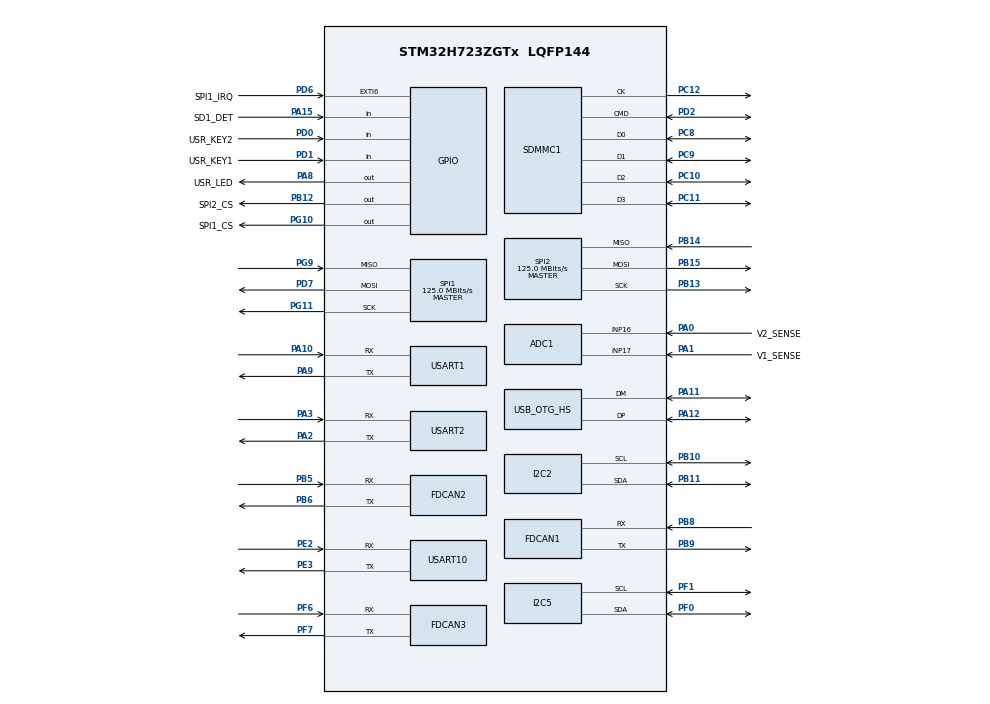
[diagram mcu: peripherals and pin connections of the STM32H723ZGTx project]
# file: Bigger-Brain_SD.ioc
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ADC1.Channel-1\#ChannelRegularConversion=ADC_CHANNEL_17
ADC1.NbrOfConversionFlag=1
ADC1.OffsetNumber-1\#ChannelRegularConversion=ADC_OFFSET_NONE
ADC1.OffsetSignedSaturation-1\#ChannelRegularConversion=DISABLE
ADC1.Rank-1\#ChannelRegularConversion=1
ADC1.SamplingTime-1\#ChannelRegularConversion=ADC_SAMPLETIME_1CYCLE_5
ADC1.master=1
FATFS.BSP.number=1
FATFS._MAX_SS=1024
FATFS0.BSP.STBoard=false
FATFS0.BSP.api=Unknown
FATFS0.BSP.instance=PA15(JTDI)
FATFS0.BSP.ip=GPIO
FATFS0.BSP.mode=Input
FATFS0.BSP.name=Detect_SDIO
FATFS0.BSP.solution=PA15(JTDI)
FDCAN1.CalculateBaudRateNominal=312500
FDCAN1.CalculateTimeBitNominal=3200
FDCAN1.CalculateTimeQuantumNominal=640.0
FDCAN2.CalculateBaudRateNominal=312500
FDCAN2.CalculateTimeBitNominal=3200
FDCAN2.CalculateTimeQuantumNominal=640.0
FDCAN3.CalculateBaudRateNominal=312500
FDCAN3.CalculateTimeBitNominal=3200
FDCAN3.CalculateTimeQuantumNominal=640.0
I2C2.Timing=0x20A0A3F6
I2C5.Timing=0x20A0A3F6
Mcu.Family=STM32H7
Mcu.Name=STM32H723ZGTx
Mcu.Package=LQFP144
NVIC.OTG_HS_IRQn=true\:0\:0\:false\:false\:true\:false\:true\:true
NVIC.PriorityGroup=NVIC_PRIORITYGROUP_4
PA0.GPIO_Label=V2_SENSE
PA0.Mode=IN16-Single-Ended
PA0.Signal=ADC1_INP16
PA1.GPIO_Label=V1_SENSE
PA1.Mode=IN17-Single-Ended
PA1.Signal=ADC1_INP17
PA10.Mode=Asynchronous
PA10.Signal=USART1_RX
PA11.Mode=Device_Only_FS
PA11.Signal=USB_OTG_HS_DM
PA12.Mode=Device_Only_FS
PA12.Signal=USB_OTG_HS_DP
PA13(JTMS/SWDIO).Mode=Serial_Wire
PA13(JTMS/SWDIO).Signal=DEBUG_JTMS-SWDIO
PA14(JTCK/SWCLK).Mode=Serial_Wire
PA14(JTCK/SWCLK).Signal=DEBUG_JTCK-SWCLK
PA15(JTDI).GPIO_Label=SD1_DET
PA15(JTDI).GPIO_PuPd=GPIO_PULLUP
PA15(JTDI).Signal=GPIO_Input
PA2.Mode=Asynchronous
PA2.Signal=USART2_TX
PA3.Mode=Asynchronous
PA3.Signal=USART2_RX
PA8.GPIO_Label=USR_LED
PA8.GPIO_ModeDefaultOutputPP=GPIO_MODE_OUTPUT_OD
PA8.GPIO_PuPd=GPIO_NOPULL
PA8.Signal=GPIO_Output
PA9.Mode=Asynchronous
PA9.Signal=USART1_TX
PB10.Mode=I2C
PB10.Signal=I2C2_SCL
PB11.Mode=I2C
PB11.Signal=I2C2_SDA
PB12.GPIO_Label=SPI2_CS
PB12.Signal=GPIO_Output
PB13.Mode=Full_Duplex_Master
PB13.Signal=SPI2_SCK
PB14.Mode=Full_Duplex_Master
PB14.Signal=SPI2_MISO
PB15.Mode=Full_Duplex_Master
PB15.Signal=SPI2_MOSI
PB5.Mode=FDCAN_Activate
PB5.Signal=FDCAN2_RX
PB6.Mode=FDCAN_Activate
PB6.Signal=FDCAN2_TX
PB8.Mode=FDCAN_Activate
PB8.Signal=FDCAN1_RX
PB9.Mode=FDCAN_Activate
PB9.Signal=FDCAN1_TX
PC10.Mode=SD_4_bits_Wide_bus
PC10.Signal=SDMMC1_D2
PC11.Mode=SD_4_bits_Wide_bus
PC11.Signal=SDMMC1_D3
PC12.Mode=SD_4_bits_Wide_bus
PC12.Signal=SDMMC1_CK
PC14-OSC32_IN.Mode=LSE-External-Oscillator
PC14-OSC32_IN.Signal=RCC_OSC32_IN
PC15-OSC32_OUT.Mode=LSE-External-Oscillator
PC15-OSC32_OUT.Signal=RCC_OSC32_OUT
PC8.Mode=SD_4_bits_Wide_bus
PC8.Signal=SDMMC1_D0
PC9.Mode=SD_4_bits_Wide_bus
PC9.Signal=SDMMC1_D1
PD0.GPIO_Label=USR_KEY2
PD0.GPIO_PuPd=GPIO_NOPULL
PD0.Signal=GPIO_Input
PD1.GPIO_Label=USR_KEY1
PD1.Signal=GPIO_Input
PD2.Mode=SD_4_bits_Wide_bus
PD2.Signal=SDMMC1_CMD
PD6.GPIO_Label=SPI1_IRQ
PD6.Signal=GPXTI6
PD7.Mode=Full_Duplex_Master
PD7.Signal=SPI1_MOSI
PE2.Mode=Asynchronous
PE2.Signal=USART10_RX
PE3.Mode=Asynchronous
PE3.Signal=USART10_TX
PF0.Mode=I2C
PF0.Signal=I2C5_SDA
PF1.Mode=I2C
PF1.Signal=I2C5_SCL
PF6.Mode=FDCAN_Activate
PF6.Signal=FDCAN3_RX
PF7.Mode=FDCAN_Activate
PF7.Signal=FDCAN3_TX
PG10.GPIO_Label=SPI1_CS
PG10.GPIO_PuPd=GPIO_PULLUP
PG10.GPIO_Speed=GPIO_SPEED_FREQ_HIGH
PG10.PinState=GPIO_PIN_SET
PG10.Signal=GPIO_Output
PG11.Mode=Full_Duplex_Master
PG11.Signal=SPI1_SCK
PG9.Mode=Full_Duplex_Master
PG9.Signal=SPI1_MISO
PH0-OSC_IN.Mode=HSE-External-Clock-Source
PH0-OSC_IN.Signal=RCC_OSC_IN
PWR.PVDLevel=PWR_PVDLEVEL_6
ProjectManager.HeapSize=0x200
ProjectManager.StackSize=0x400
ProjectManager.TargetToolchain=STM32CubeIDE
RCC.ADCFreq_Value=96000000
RCC.APB1Freq_Value=125000000
RCC.APB2Freq_Value=125000000
RCC.APB3Freq_Value=125000000
RCC.APB4Freq_Value=125000000
RCC.CortexFreq_Value=500000000
RCC.D1PPRE=RCC_APB3_DIV2
RCC.D2PPRE1=RCC_APB1_DIV2
RCC.D2PPRE2=RCC_APB2_DIV2
RCC.D3PPRE=RCC_APB4_DIV2
RCC.DATA_CACHE_ENABLE=1
RCC.DIVM1=4
RCC.DIVM2=4
RCC.DIVN1=31
RCC.DIVN2=12
RCC.DIVP1=1
RCC.FDCANCLockSelection=RCC_FDCANCLKSOURCE_HSE
RCC.HCLKFreq_Value=250000000
RCC.HPRE=RCC_HCLK_DIV2
RCC.HSE_VALUE=25000000
RCC.INSTRUCTION_CACHE_ENABLE=1
RCC.PLL1_VCI_Range-AdvancedSettings=RCC_PLL1VCIRANGE_1
RCC.PLL1_VCO_SEL-AdvancedSettings=RCC_PLL1VCOMEDIUM
RCC.PLL2FRACN=0
RCC.PLL2_VCI_Range-AdvancedSettings=RCC_PLL2VCIRANGE_1
RCC.PLL2_VCO_SEL-AdvancedSettings=RCC_PLL2VCOWIDE
RCC.PLL3FRACN=0
RCC.PLL3_VCO_SEL-AdvancedSettings=RCC_PLL3VCOMEDIUM
RCC.PLLFRACN=2048
RCC.PREFETCH_ENABLE=1
RCC.PWREXT_OverDrive=PWREXT_OverDrive_DESACTIVATED
RCC.PWR_Regulator_Voltage_Scale=PWR_REGULATOR_VOLTAGE_SCALE0
RCC.ProductRev=revV
RCC.RCC_TIM_PRescaler_Selection=RCC_TIMPRES_ACTIVATED
RCC.SDMMC1CLockSelection=RCC_SDMMCCLKSOURCE_PLL2
RCC.SYSCLKFreq_VALUE=500000000
RCC.SYSCLKSource=RCC_SYSCLKSOURCE_PLLCLK
RCC.SupplySource=PWR_LDO_SUPPLY
RCC.USBCLockSelection=RCC_USBCLKSOURCE_HSI48
RCC.USBFreq_Value=48000000
SDMMC1.ClockDiv=4
SPI1.CalculateBaudRate=125.0 MBits/s
SPI1.Direction=SPI_DIRECTION_2LINES
SPI1.Mode=SPI_MODE_MASTER
SPI1.VirtualType=VM_MASTER
SPI2.CalculateBaudRate=125.0 MBits/s
SPI2.Direction=SPI_DIRECTION_2LINES
SPI2.Mode=SPI_MODE_MASTER
SPI2.VirtualType=VM_MASTER
USART1.VirtualMode-Asynchronous=VM_ASYNC
USART10.VirtualMode-Asynchronous=VM_ASYNC
USART2.VirtualMode-Asynchronous=VM_ASYNC
USB_DEVICE.CLASS_NAME_HS=CDC
USB_DEVICE.MANUFACTURER_STRING=Bigger-Brain
USB_DEVICE.PRODUCT_STRING_CDC_HS=Scott CJX
USB_DEVICE.VirtualMode=Cdc
USB_DEVICE.VirtualModeHS=Cdc_HS
USB_OTG_HS.VirtualMode-Device_Only_FS=Device_Only_FS
VP_FATFS_VS_SDIO.Mode=SDIO
VP_PWR_V_PVD_IN.Mode=Mode_PVD_Int
VP_USB_DEVICE_VS_USB_DEVICE_CDC_HS.Mode=CDC_HS
board=custom

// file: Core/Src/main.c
/* USER CODE BEGIN Header */
/**
 ******************************************************************************
 * @file           : main.c
 * @brief          : Main program body
 ******************************************************************************
 * @attention
 *
 * Copyright (c) 2024 STMicroelectronics.
 * All rights reserved.
 *
 * This software is licensed under terms that can be found in the LICENSE file
 * in the root directory of this software component.
 * If no LICENSE file comes with this software, it is provided AS-IS.
 *
 ******************************************************************************
 */
/* USER CODE END Header */
#include "main.h"
#include "fatfs.h"
#include "usb_device.h"

/* USER CODE BEGIN Includes */

// #include "usbd_cdc_if.h"
// #include "ffconf.h"

// #include <stdio.h>
// #include <stdlib.h>
// #include <string.h>

// moved to app_sdcard

/* USER CODE END Includes */

ADC_HandleTypeDef hadc1;

FDCAN_HandleTypeDef hfdcan1;
FDCAN_HandleTypeDef hfdcan2;
FDCAN_HandleTypeDef hfdcan3;

I2C_HandleTypeDef hi2c2;
I2C_HandleTypeDef hi2c5;

SD_HandleTypeDef hsd1;

SPI_HandleTypeDef hspi1;
SPI_HandleTypeDef hspi2;

UART_HandleTypeDef huart1;
UART_HandleTypeDef huart2;
UART_HandleTypeDef huart10;

void SystemClock_Config(void);
void PeriphCommonClock_Config(void);
static void MX_GPIO_Init(void);
static void MX_FDCAN1_Init(void);
static void MX_FDCAN2_Init(void);
static void MX_FDCAN3_Init(void);
static void MX_SDMMC1_SD_Init(void);
static void MX_I2C2_Init(void);
static void MX_SPI2_Init(void);
static void MX_USART1_UART_Init(void);
static void MX_USART2_UART_Init(void);
static void MX_ADC1_Init(void);
static void MX_I2C5_Init(void);
static void MX_SPI1_Init(void);
static void MX_USART10_UART_Init(void);

/* USER CODE BEGIN 0 */

// /* Function to read directory contents and transmit via CDC */
// int read_directory(char *path)
// {
//   DIR dir;
//   FILINFO fno;
//   FRESULT res;

//   if (f_opendir(&dir, path) != FR_OK)
//   {
//     CDC_Transmit_HS((uint8_t *)"Failed to open directory\n", strlen("Failed to open directory\n"));
//     return 1;
//   }

//   while ((res = f_readdir(&dir, &fno)) == FR_OK && fno.fname[0] != 0)
//   {
//     if (fno.fattrib & AM_DIR)
//     {
//       // Directory
//       CDC_Transmit_HS((uint8_t *)"\t<DIR> ", strlen("\t<DIR> "));
//     }
//     else
//     {
//       // File
//       CDC_Transmit_HS((uint8_t *)"\t", strlen("\t"));
//     }
//     CDC_Transmit_HS((uint8_t *)fno.fname, strlen(fno.fname));
//     CDC_Transmit_HS((uint8_t *)"\n", strlen("\n"));
//   }

//   f_closedir(&dir); // Close the directory

//   return 0;
// }

// /* Function to read a file on the SD card and transmit via CDC */
// int read_file(char *filename) {
//   FIL file;
//   FRESULT res;
//   UINT bytes_read;
//   char buffer[512]; // Adjust buffer size as needed

//   if (f_open(&file, filename, FA_READ) != FR_OK) {
//     CDC_Transmit_HS((uint8_t *)"Failed to open file: ", strlen("Failed to open file: "));
//     CDC_Transmit_HS((uint8_t *)filename, strlen(filename));
//     CDC_Transmit_HS((uint8_t *)"\n", strlen("\n"));
//     return 1;
//   }

//   // Read the file content into the buffer
//   while ((res = f_read(&file, buffer, sizeof(buffer), &bytes_read)) == FR_OK && bytes_read > 0) {
//     // Transmit the read data via CDC
//     CDC_Transmit_HS((uint8_t *)buffer, bytes_read);
//   }

//   if (res != FR_OK) {
//     CDC_Transmit_HS((uint8_t *)"Error reading file: ", strlen("Error reading file: "));
//     CDC_Transmit_HS((uint8_t *)filename, strlen(filename));
//     CDC_Transmit_HS((uint8_t *)"\n", strlen("\n"));
//     f_close(&file);
//     return 1;
//   }

//   CDC_Transmit_HS((uint8_t *)"Finished reading file: ", strlen("Finished reading file: "));
//   CDC_Transmit_HS((uint8_t *)filename, strlen(filename));
//   CDC_Transmit_HS((uint8_t *)"\n", strlen("\n"));
//   f_close(&file);

//   return 0;
// }

// moved to app_sdcard

/* USER CODE END 0 */

int main(void)
{

  /* MCU Configuration--------------------------------------------------------*/

  /* Reset of all peripherals, Initializes the Flash interface and the Systick. */
  HAL_Init();

  /* Configure the system clock */
  SystemClock_Config();

/* Configure the peripherals common clocks */
  PeriphCommonClock_Config();

  /* Initialize all configured peripherals */
  MX_GPIO_Init();
  MX_FDCAN1_Init();
  MX_FDCAN2_Init();
  MX_FDCAN3_Init();
  MX_SDMMC1_SD_Init();
  MX_I2C2_Init();
  MX_SPI2_Init();
  MX_USART1_UART_Init();
  MX_USART2_UART_Init();
  MX_ADC1_Init();
  MX_I2C5_Init();
  MX_SPI1_Init();
  MX_USART10_UART_Init();
  MX_USB_DEVICE_Init();
  MX_FATFS_Init();

  /* Infinite loop */
  while (1)
  {

    /* USER CODE BEGIN 3 */
//
    if (HAL_GPIO_ReadPin(USR_KEY1_GPIO_Port, USR_KEY1_Pin))
    {

      // todo

      while (HAL_GPIO_ReadPin(USR_KEY1_GPIO_Port, USR_KEY1_Pin))
      {
        ;
      }
    }

    HAL_GPIO_WritePin(USR_LED_GPIO_Port, USR_LED_Pin, HAL_GPIO_ReadPin(SD1_DET_GPIO_Port, SD1_DET_Pin));
    HAL_Delay(500);
  }
  /* USER CODE END 3 */
}

void SystemClock_Config(void)
{
  RCC_OscInitTypeDef RCC_OscInitStruct = {0};
  RCC_ClkInitTypeDef RCC_ClkInitStruct = {0};

  /** Supply configuration update enable
  */
  HAL_PWREx_ConfigSupply(PWR_LDO_SUPPLY);

  /** Configure the main internal regulator output voltage
  */
  __HAL_PWR_VOLTAGESCALING_CONFIG(PWR_REGULATOR_VOLTAGE_SCALE0);

  while(!__HAL_PWR_GET_FLAG(PWR_FLAG_VOSRDY)) {}

  /** Initializes the RCC Oscillators according to the specified parameters
  * in the RCC_OscInitTypeDef structure.
  */
  RCC_OscInitStruct.OscillatorType = RCC_OSCILLATORTYPE_HSI48|RCC_OSCILLATORTYPE_HSI
                              |RCC_OSCILLATORTYPE_HSE;
  RCC_OscInitStruct.HSEState = RCC_HSE_BYPASS;
  RCC_OscInitStruct.HSIState = RCC_HSI_DIV1;
  RCC_OscInitStruct.HSICalibrationValue = 64;
  RCC_OscInitStruct.HSI48State = RCC_HSI48_ON;
  RCC_OscInitStruct.PLL.PLLState = RCC_PLL_ON;
  RCC_OscInitStruct.PLL.PLLSource = RCC_PLLSOURCE_HSI;
  RCC_OscInitStruct.PLL.PLLM = 4;
  RCC_OscInitStruct.PLL.PLLN = 31;
  RCC_OscInitStruct.PLL.PLLP = 1;
  RCC_OscInitStruct.PLL.PLLQ = 2;
  RCC_OscInitStruct.PLL.PLLR = 2;
  RCC_OscInitStruct.PLL.PLLRGE = RCC_PLL1VCIRANGE_3;
  RCC_OscInitStruct.PLL.PLLVCOSEL = RCC_PLL1VCOWIDE;
  RCC_OscInitStruct.PLL.PLLFRACN = 2048;
  if (HAL_RCC_OscConfig(&RCC_OscInitStruct) != HAL_OK)
  {
    Error_Handler();
  }

  /** Initializes the CPU, AHB and APB buses clocks
  */
  RCC_ClkInitStruct.ClockType = RCC_CLOCKTYPE_HCLK|RCC_CLOCKTYPE_SYSCLK
                              |RCC_CLOCKTYPE_PCLK1|RCC_CLOCKTYPE_PCLK2
                              |RCC_CLOCKTYPE_D3PCLK1|RCC_CLOCKTYPE_D1PCLK1;
  RCC_ClkInitStruct.SYSCLKSource = RCC_SYSCLKSOURCE_PLLCLK;
  RCC_ClkInitStruct.SYSCLKDivider = RCC_SYSCLK_DIV1;
  RCC_ClkInitStruct.AHBCLKDivider = RCC_HCLK_DIV2;
  RCC_ClkInitStruct.APB3CLKDivider = RCC_APB3_DIV2;
  RCC_ClkInitStruct.APB1CLKDivider = RCC_APB1_DIV2;
  RCC_ClkInitStruct.APB2CLKDivider = RCC_APB2_DIV2;
  RCC_ClkInitStruct.APB4CLKDivider = RCC_APB4_DIV2;

  if (HAL_RCC_ClockConfig(&RCC_ClkInitStruct, FLASH_LATENCY_3) != HAL_OK)
  {
    Error_Handler();
  }
}

void PeriphCommonClock_Config(void)
{
  RCC_PeriphCLKInitTypeDef PeriphClkInitStruct = {0};

  /** Initializes the peripherals clock
  */
  PeriphClkInitStruct.PeriphClockSelection = RCC_PERIPHCLK_ADC|RCC_PERIPHCLK_SDMMC
                              |RCC_PERIPHCLK_TIM;
  PeriphClkInitStruct.PLL2.PLL2M = 4;
  PeriphClkInitStruct.PLL2.PLL2N = 12;
  PeriphClkInitStruct.PLL2.PLL2P = 2;
  PeriphClkInitStruct.PLL2.PLL2Q = 2;
  PeriphClkInitStruct.PLL2.PLL2R = 2;
  PeriphClkInitStruct.PLL2.PLL2RGE = RCC_PLL2VCIRANGE_3;
  PeriphClkInitStruct.PLL2.PLL2VCOSEL = RCC_PLL2VCOWIDE;
  PeriphClkInitStruct.PLL2.PLL2FRACN = 0;
  PeriphClkInitStruct.SdmmcClockSelection = RCC_SDMMCCLKSOURCE_PLL2;
  PeriphClkInitStruct.AdcClockSelection = RCC_ADCCLKSOURCE_PLL2;
  PeriphClkInitStruct.TIMPresSelection = RCC_TIMPRES_ACTIVATED;

  if (HAL_RCCEx_PeriphCLKConfig(&PeriphClkInitStruct) != HAL_OK)
  {
    Error_Handler();
  }
}

static void MX_ADC1_Init(void)
{

  ADC_MultiModeTypeDef multimode = {0};
  ADC_ChannelConfTypeDef sConfig = {0};

  /** Common config
  */
  hadc1.Instance = ADC1;
  hadc1.Init.ClockPrescaler = ADC_CLOCK_ASYNC_DIV1;
  hadc1.Init.Resolution = ADC_RESOLUTION_16B;
  hadc1.Init.ScanConvMode = ADC_SCAN_DISABLE;
  hadc1.Init.EOCSelection = ADC_EOC_SINGLE_CONV;
  hadc1.Init.LowPowerAutoWait = DISABLE;
  hadc1.Init.ContinuousConvMode = DISABLE;
  hadc1.Init.NbrOfConversion = 1;
  hadc1.Init.DiscontinuousConvMode = DISABLE;
  hadc1.Init.ExternalTrigConv = ADC_SOFTWARE_START;
  hadc1.Init.ExternalTrigConvEdge = ADC_EXTERNALTRIGCONVEDGE_NONE;
  hadc1.Init.ConversionDataManagement = ADC_CONVERSIONDATA_DR;
  hadc1.Init.Overrun = ADC_OVR_DATA_PRESERVED;
  hadc1.Init.LeftBitShift = ADC_LEFTBITSHIFT_NONE;
  hadc1.Init.OversamplingMode = DISABLE;
  if (HAL_ADC_Init(&hadc1) != HAL_OK)
  {
    Error_Handler();
  }

  /** Configure the ADC multi-mode
  */
  multimode.Mode = ADC_MODE_INDEPENDENT;
  if (HAL_ADCEx_MultiModeConfigChannel(&hadc1, &multimode) != HAL_OK)
  {
    Error_Handler();
  }

  /** Configure Regular Channel
  */
  sConfig.Channel = ADC_CHANNEL_17;
  sConfig.Rank = ADC_REGULAR_RANK_1;
  sConfig.SamplingTime = ADC_SAMPLETIME_1CYCLE_5;
  sConfig.SingleDiff = ADC_SINGLE_ENDED;
  sConfig.OffsetNumber = ADC_OFFSET_NONE;
  sConfig.Offset = 0;
  sConfig.OffsetSignedSaturation = DISABLE;
  if (HAL_ADC_ConfigChannel(&hadc1, &sConfig) != HAL_OK)
  {
    Error_Handler();
  }

}

static void MX_FDCAN1_Init(void)
{

  hfdcan1.Instance = FDCAN1;
  hfdcan1.Init.FrameFormat = FDCAN_FRAME_CLASSIC;
  hfdcan1.Init.Mode = FDCAN_MODE_NORMAL;
  hfdcan1.Init.AutoRetransmission = DISABLE;
  hfdcan1.Init.TransmitPause = DISABLE;
  hfdcan1.Init.ProtocolException = DISABLE;
  hfdcan1.Init.NominalPrescaler = 16;
  hfdcan1.Init.NominalSyncJumpWidth = 1;
  hfdcan1.Init.NominalTimeSeg1 = 2;
  hfdcan1.Init.NominalTimeSeg2 = 2;
  hfdcan1.Init.DataPrescaler = 1;
  hfdcan1.Init.DataSyncJumpWidth = 1;
  hfdcan1.Init.DataTimeSeg1 = 1;
  hfdcan1.Init.DataTimeSeg2 = 1;
  hfdcan1.Init.MessageRAMOffset = 0;
  hfdcan1.Init.StdFiltersNbr = 0;
  hfdcan1.Init.ExtFiltersNbr = 0;
  hfdcan1.Init.RxFifo0ElmtsNbr = 0;
  hfdcan1.Init.RxFifo0ElmtSize = FDCAN_DATA_BYTES_8;
  hfdcan1.Init.RxFifo1ElmtsNbr = 0;
  hfdcan1.Init.RxFifo1ElmtSize = FDCAN_DATA_BYTES_8;
  hfdcan1.Init.RxBuffersNbr = 0;
  hfdcan1.Init.RxBufferSize = FDCAN_DATA_BYTES_8;
  hfdcan1.Init.TxEventsNbr = 0;
  hfdcan1.Init.TxBuffersNbr = 0;
  hfdcan1.Init.TxFifoQueueElmtsNbr = 0;
  hfdcan1.Init.TxFifoQueueMode = FDCAN_TX_FIFO_OPERATION;
  hfdcan1.Init.TxElmtSize = FDCAN_DATA_BYTES_8;
  if (HAL_FDCAN_Init(&hfdcan1) != HAL_OK)
  {
    Error_Handler();
  }

}

static void MX_FDCAN2_Init(void)
{

  hfdcan2.Instance = FDCAN2;
  hfdcan2.Init.FrameFormat = FDCAN_FRAME_CLASSIC;
  hfdcan2.Init.Mode = FDCAN_MODE_NORMAL;
  hfdcan2.Init.AutoRetransmission = DISABLE;
  hfdcan2.Init.TransmitPause = DISABLE;
  hfdcan2.Init.ProtocolException = DISABLE;
  hfdcan2.Init.NominalPrescaler = 16;
  hfdcan2.Init.NominalSyncJumpWidth = 1;
  hfdcan2.Init.NominalTimeSeg1 = 2;
  hfdcan2.Init.NominalTimeSeg2 = 2;
  hfdcan2.Init.DataPrescaler = 1;
  hfdcan2.Init.DataSyncJumpWidth = 1;
  hfdcan2.Init.DataTimeSeg1 = 1;
  hfdcan2.Init.DataTimeSeg2 = 1;
  hfdcan2.Init.MessageRAMOffset = 0;
  hfdcan2.Init.StdFiltersNbr = 0;
  hfdcan2.Init.ExtFiltersNbr = 0;
  hfdcan2.Init.RxFifo0ElmtsNbr = 0;
  hfdcan2.Init.RxFifo0ElmtSize = FDCAN_DATA_BYTES_8;
  hfdcan2.Init.RxFifo1ElmtsNbr = 0;
  hfdcan2.Init.RxFifo1ElmtSize = FDCAN_DATA_BYTES_8;
  hfdcan2.Init.RxBuffersNbr = 0;
  hfdcan2.Init.RxBufferSize = FDCAN_DATA_BYTES_8;
  hfdcan2.Init.TxEventsNbr = 0;
  hfdcan2.Init.TxBuffersNbr = 0;
  hfdcan2.Init.TxFifoQueueElmtsNbr = 0;
  hfdcan2.Init.TxFifoQueueMode = FDCAN_TX_FIFO_OPERATION;
  hfdcan2.Init.TxElmtSize = FDCAN_DATA_BYTES_8;
  if (HAL_FDCAN_Init(&hfdcan2) != HAL_OK)
  {
    Error_Handler();
  }

}

static void MX_FDCAN3_Init(void)
{

  hfdcan3.Instance = FDCAN3;
  hfdcan3.Init.FrameFormat = FDCAN_FRAME_CLASSIC;
  hfdcan3.Init.Mode = FDCAN_MODE_NORMAL;
  hfdcan3.Init.AutoRetransmission = DISABLE;
  hfdcan3.Init.TransmitPause = DISABLE;
  hfdcan3.Init.ProtocolException = DISABLE;
  hfdcan3.Init.NominalPrescaler = 16;
  hfdcan3.Init.NominalSyncJumpWidth = 1;
  hfdcan3.Init.NominalTimeSeg1 = 2;
  hfdcan3.Init.NominalTimeSeg2 = 2;
  hfdcan3.Init.DataPrescaler = 1;
  hfdcan3.Init.DataSyncJumpWidth = 1;
  hfdcan3.Init.DataTimeSeg1 = 1;
  hfdcan3.Init.DataTimeSeg2 = 1;
  hfdcan3.Init.MessageRAMOffset = 0;
  hfdcan3.Init.StdFiltersNbr = 0;
  hfdcan3.Init.ExtFiltersNbr = 0;
  hfdcan3.Init.RxFifo0ElmtsNbr = 0;
  hfdcan3.Init.RxFifo0ElmtSize = FDCAN_DATA_BYTES_8;
  hfdcan3.Init.RxFifo1ElmtsNbr = 0;
  hfdcan3.Init.RxFifo1ElmtSize = FDCAN_DATA_BYTES_8;
  hfdcan3.Init.RxBuffersNbr = 0;
  hfdcan3.Init.RxBufferSize = FDCAN_DATA_BYTES_8;
  hfdcan3.Init.TxEventsNbr = 0;
  hfdcan3.Init.TxBuffersNbr = 0;
  hfdcan3.Init.TxFifoQueueElmtsNbr = 0;
  hfdcan3.Init.TxFifoQueueMode = FDCAN_TX_FIFO_OPERATION;
  hfdcan3.Init.TxElmtSize = FDCAN_DATA_BYTES_8;
  if (HAL_FDCAN_Init(&hfdcan3) != HAL_OK)
  {
    Error_Handler();
  }

}

static void MX_I2C2_Init(void)
{

  hi2c2.Instance = I2C2;
  hi2c2.Init.Timing = 0x20A0A3F6;
  hi2c2.Init.OwnAddress1 = 0;
  hi2c2.Init.AddressingMode = I2C_ADDRESSINGMODE_7BIT;
  hi2c2.Init.DualAddressMode = I2C_DUALADDRESS_DISABLE;
  hi2c2.Init.OwnAddress2 = 0;
  hi2c2.Init.OwnAddress2Masks = I2C_OA2_NOMASK;
  hi2c2.Init.GeneralCallMode = I2C_GENERALCALL_DISABLE;
  hi2c2.Init.NoStretchMode = I2C_NOSTRETCH_DISABLE;
  if (HAL_I2C_Init(&hi2c2) != HAL_OK)
  {
    Error_Handler();
  }

  /** Configure Analogue filter
  */
  if (HAL_I2CEx_ConfigAnalogFilter(&hi2c2, I2C_ANALOGFILTER_ENABLE) != HAL_OK)
  {
    Error_Handler();
  }

  /** Configure Digital filter
  */
  if (HAL_I2CEx_ConfigDigitalFilter(&hi2c2, 0) != HAL_OK)
  {
    Error_Handler();
  }

}

static void MX_I2C5_Init(void)
{

  hi2c5.Instance = I2C5;
  hi2c5.Init.Timing = 0x20A0A3F6;
  hi2c5.Init.OwnAddress1 = 0;
  hi2c5.Init.AddressingMode = I2C_ADDRESSINGMODE_7BIT;
  hi2c5.Init.DualAddressMode = I2C_DUALADDRESS_DISABLE;
  hi2c5.Init.OwnAddress2 = 0;
  hi2c5.Init.OwnAddress2Masks = I2C_OA2_NOMASK;
  hi2c5.Init.GeneralCallMode = I2C_GENERALCALL_DISABLE;
  hi2c5.Init.NoStretchMode = I2C_NOSTRETCH_DISABLE;
  if (HAL_I2C_Init(&hi2c5) != HAL_OK)
  {
    Error_Handler();
  }

  /** Configure Analogue filter
  */
  if (HAL_I2CEx_ConfigAnalogFilter(&hi2c5, I2C_ANALOGFILTER_ENABLE) != HAL_OK)
  {
    Error_Handler();
  }

  /** Configure Digital filter
  */
  if (HAL_I2CEx_ConfigDigitalFilter(&hi2c5, 0) != HAL_OK)
  {
    Error_Handler();
  }

}

static void MX_SDMMC1_SD_Init(void)
{

  hsd1.Instance = SDMMC1;
  hsd1.Init.ClockEdge = SDMMC_CLOCK_EDGE_RISING;
  hsd1.Init.ClockPowerSave = SDMMC_CLOCK_POWER_SAVE_DISABLE;
  hsd1.Init.BusWide = SDMMC_BUS_WIDE_4B;
  hsd1.Init.HardwareFlowControl = SDMMC_HARDWARE_FLOW_CONTROL_DISABLE;
  hsd1.Init.ClockDiv = 4;

}

static void MX_SPI1_Init(void)
{

  /* SPI1 parameter configuration*/
  hspi1.Instance = SPI1;
  hspi1.Init.Mode = SPI_MODE_MASTER;
  hspi1.Init.Direction = SPI_DIRECTION_2LINES;
  hspi1.Init.DataSize = SPI_DATASIZE_4BIT;
  hspi1.Init.CLKPolarity = SPI_POLARITY_LOW;
  hspi1.Init.CLKPhase = SPI_PHASE_1EDGE;
  hspi1.Init.NSS = SPI_NSS_SOFT;
  hspi1.Init.BaudRatePrescaler = SPI_BAUDRATEPRESCALER_2;
  hspi1.Init.FirstBit = SPI_FIRSTBIT_MSB;
  hspi1.Init.TIMode = SPI_TIMODE_DISABLE;
  hspi1.Init.CRCCalculation = SPI_CRCCALCULATION_DISABLE;
  hspi1.Init.CRCPolynomial = 0x0;
  hspi1.Init.NSSPMode = SPI_NSS_PULSE_ENABLE;
  hspi1.Init.NSSPolarity = SPI_NSS_POLARITY_LOW;
  hspi1.Init.FifoThreshold = SPI_FIFO_THRESHOLD_01DATA;
  hspi1.Init.TxCRCInitializationPattern = SPI_CRC_INITIALIZATION_ALL_ZERO_PATTERN;
  hspi1.Init.RxCRCInitializationPattern = SPI_CRC_INITIALIZATION_ALL_ZERO_PATTERN;
  hspi1.Init.MasterSSIdleness = SPI_MASTER_SS_IDLENESS_00CYCLE;
  hspi1.Init.MasterInterDataIdleness = SPI_MASTER_INTERDATA_IDLENESS_00CYCLE;
  hspi1.Init.MasterReceiverAutoSusp = SPI_MASTER_RX_AUTOSUSP_DISABLE;
  hspi1.Init.MasterKeepIOState = SPI_MASTER_KEEP_IO_STATE_DISABLE;
  hspi1.Init.IOSwap = SPI_IO_SWAP_DISABLE;
  if (HAL_SPI_Init(&hspi1) != HAL_OK)
  {
    Error_Handler();
  }

}

static void MX_SPI2_Init(void)
{

  /* SPI2 parameter configuration*/
  hspi2.Instance = SPI2;
  hspi2.Init.Mode = SPI_MODE_MASTER;
  hspi2.Init.Direction = SPI_DIRECTION_2LINES;
  hspi2.Init.DataSize = SPI_DATASIZE_4BIT;
  hspi2.Init.CLKPolarity = SPI_POLARITY_LOW;
  hspi2.Init.CLKPhase = SPI_PHASE_1EDGE;
  hspi2.Init.NSS = SPI_NSS_SOFT;
  hspi2.Init.BaudRatePrescaler = SPI_BAUDRATEPRESCALER_2;
  hspi2.Init.FirstBit = SPI_FIRSTBIT_MSB;
  hspi2.Init.TIMode = SPI_TIMODE_DISABLE;
  hspi2.Init.CRCCalculation = SPI_CRCCALCULATION_DISABLE;
  hspi2.Init.CRCPolynomial = 0x0;
  hspi2.Init.NSSPMode = SPI_NSS_PULSE_ENABLE;
  hspi2.Init.NSSPolarity = SPI_NSS_POLARITY_LOW;
  hspi2.Init.FifoThreshold = SPI_FIFO_THRESHOLD_01DATA;
  hspi2.Init.TxCRCInitializationPattern = SPI_CRC_INITIALIZATION_ALL_ZERO_PATTERN;
  hspi2.Init.RxCRCInitializationPattern = SPI_CRC_INITIALIZATION_ALL_ZERO_PATTERN;
  hspi2.Init.MasterSSIdleness = SPI_MASTER_SS_IDLENESS_00CYCLE;
  hspi2.Init.MasterInterDataIdleness = SPI_MASTER_INTERDATA_IDLENESS_00CYCLE;
  hspi2.Init.MasterReceiverAutoSusp = SPI_MASTER_RX_AUTOSUSP_DISABLE;
  hspi2.Init.MasterKeepIOState = SPI_MASTER_KEEP_IO_STATE_DISABLE;
  hspi2.Init.IOSwap = SPI_IO_SWAP_DISABLE;
  if (HAL_SPI_Init(&hspi2) != HAL_OK)
  {
    Error_Handler();
  }

}

static void MX_USART1_UART_Init(void)
{

  huart1.Instance = USART1;
  huart1.Init.BaudRate = 115200;
  huart1.Init.WordLength = UART_WORDLENGTH_8B;
  huart1.Init.StopBits = UART_STOPBITS_1;
  huart1.Init.Parity = UART_PARITY_NONE;
  huart1.Init.Mode = UART_MODE_TX_RX;
  huart1.Init.HwFlowCtl = UART_HWCONTROL_NONE;
  huart1.Init.OverSampling = UART_OVERSAMPLING_16;
  huart1.Init.OneBitSampling = UART_ONE_BIT_SAMPLE_DISABLE;
  huart1.Init.ClockPrescaler = UART_PRESCALER_DIV1;
  huart1.AdvancedInit.AdvFeatureInit = UART_ADVFEATURE_NO_INIT;
  if (HAL_UART_Init(&huart1) != HAL_OK)
  {
    Error_Handler();
  }
  if (HAL_UARTEx_SetTxFifoThreshold(&huart1, UART_TXFIFO_THRESHOLD_1_8) != HAL_OK)
  {
    Error_Handler();
  }
  if (HAL_UARTEx_SetRxFifoThreshold(&huart1, UART_RXFIFO_THRESHOLD_1_8) != HAL_OK)
  {
    Error_Handler();
  }
  if (HAL_UARTEx_DisableFifoMode(&huart1) != HAL_OK)
  {
    Error_Handler();
  }

}

static void MX_USART2_UART_Init(void)
{

  huart2.Instance = USART2;
  huart2.Init.BaudRate = 115200;
  huart2.Init.WordLength = UART_WORDLENGTH_8B;
  huart2.Init.StopBits = UART_STOPBITS_1;
  huart2.Init.Parity = UART_PARITY_NONE;
  huart2.Init.Mode = UART_MODE_TX_RX;
  huart2.Init.HwFlowCtl = UART_HWCONTROL_NONE;
  huart2.Init.OverSampling = UART_OVERSAMPLING_16;
  huart2.Init.OneBitSampling = UART_ONE_BIT_SAMPLE_DISABLE;
  huart2.Init.ClockPrescaler = UART_PRESCALER_DIV1;
  huart2.AdvancedInit.AdvFeatureInit = UART_ADVFEATURE_NO_INIT;
  if (HAL_UART_Init(&huart2) != HAL_OK)
  {
    Error_Handler();
  }
  if (HAL_UARTEx_SetTxFifoThreshold(&huart2, UART_TXFIFO_THRESHOLD_1_8) != HAL_OK)
  {
    Error_Handler();
  }
  if (HAL_UARTEx_SetRxFifoThreshold(&huart2, UART_RXFIFO_THRESHOLD_1_8) != HAL_OK)
  {
    Error_Handler();
  }
  if (HAL_UARTEx_DisableFifoMode(&huart2) != HAL_OK)
  {
    Error_Handler();
  }

}

static void MX_USART10_UART_Init(void)
{

  huart10.Instance = USART10;
  huart10.Init.BaudRate = 115200;
  huart10.Init.WordLength = UART_WORDLENGTH_8B;
  huart10.Init.StopBits = UART_STOPBITS_1;
  huart10.Init.Parity = UART_PARITY_NONE;
  huart10.Init.Mode = UART_MODE_TX_RX;
  huart10.Init.HwFlowCtl = UART_HWCONTROL_NONE;
  huart10.Init.OverSampling = UART_OVERSAMPLING_16;
  huart10.Init.OneBitSampling = UART_ONE_BIT_SAMPLE_DISABLE;
  huart10.Init.ClockPrescaler = UART_PRESCALER_DIV1;
  huart10.AdvancedInit.AdvFeatureInit = UART_ADVFEATURE_NO_INIT;
  if (HAL_UART_Init(&huart10) != HAL_OK)
  {
    Error_Handler();
  }
  if (HAL_UARTEx_SetTxFifoThreshold(&huart10, UART_TXFIFO_THRESHOLD_1_8) != HAL_OK)
  {
    Error_Handler();
  }
  if (HAL_UARTEx_SetRxFifoThreshold(&huart10, UART_RXFIFO_THRESHOLD_1_8) != HAL_OK)
  {
    Error_Handler();
  }
  if (HAL_UARTEx_DisableFifoMode(&huart10) != HAL_OK)
  {
    Error_Handler();
  }

}

static void MX_GPIO_Init(void)
{
  GPIO_InitTypeDef GPIO_InitStruct = {0};

  /* GPIO Ports Clock Enable */
  __HAL_RCC_GPIOE_CLK_ENABLE();
  __HAL_RCC_GPIOC_CLK_ENABLE();
  __HAL_RCC_GPIOF_CLK_ENABLE();
  __HAL_RCC_GPIOH_CLK_ENABLE();
  __HAL_RCC_GPIOA_CLK_ENABLE();
  __HAL_RCC_GPIOB_CLK_ENABLE();
  __HAL_RCC_GPIOD_CLK_ENABLE();
  __HAL_RCC_GPIOG_CLK_ENABLE();

  /*Configure GPIO pin Output Level */
  HAL_GPIO_WritePin(SPI2_CS_GPIO_Port, SPI2_CS_Pin, GPIO_PIN_RESET);

  /*Configure GPIO pin Output Level */
  HAL_GPIO_WritePin(USR_LED_GPIO_Port, USR_LED_Pin, GPIO_PIN_RESET);

  /*Configure GPIO pin Output Level */
  HAL_GPIO_WritePin(SPI1_CS_GPIO_Port, SPI1_CS_Pin, GPIO_PIN_SET);

  /*Configure GPIO pin : SPI2_CS_Pin */
  GPIO_InitStruct.Pin = SPI2_CS_Pin;
  GPIO_InitStruct.Mode = GPIO_MODE_OUTPUT_PP;
  GPIO_InitStruct.Pull = GPIO_NOPULL;
  GPIO_InitStruct.Speed = GPIO_SPEED_FREQ_LOW;
  HAL_GPIO_Init(SPI2_CS_GPIO_Port, &GPIO_InitStruct);

  /*Configure GPIO pin : USR_LED_Pin */
  GPIO_InitStruct.Pin = USR_LED_Pin;
  GPIO_InitStruct.Mode = GPIO_MODE_OUTPUT_OD;
  GPIO_InitStruct.Pull = GPIO_NOPULL;
  GPIO_InitStruct.Speed = GPIO_SPEED_FREQ_LOW;
  HAL_GPIO_Init(USR_LED_GPIO_Port, &GPIO_InitStruct);

  /*Configure GPIO pin : SD1_DET_Pin */
  GPIO_InitStruct.Pin = SD1_DET_Pin;
  GPIO_InitStruct.Mode = GPIO_MODE_INPUT;
  GPIO_InitStruct.Pull = GPIO_PULLUP;
  HAL_GPIO_Init(SD1_DET_GPIO_Port, &GPIO_InitStruct);

  /*Configure GPIO pins : USR_KEY2_Pin USR_KEY1_Pin */
  GPIO_InitStruct.Pin = USR_KEY2_Pin|USR_KEY1_Pin;
  GPIO_InitStruct.Mode = GPIO_MODE_INPUT;
  GPIO_InitStruct.Pull = GPIO_NOPULL;
  HAL_GPIO_Init(GPIOD, &GPIO_InitStruct);

  /*Configure GPIO pin : SPI1_IRQ_Pin */
  GPIO_InitStruct.Pin = SPI1_IRQ_Pin;
  GPIO_InitStruct.Mode = GPIO_MODE_IT_RISING;
  GPIO_InitStruct.Pull = GPIO_NOPULL;
  HAL_GPIO_Init(SPI1_IRQ_GPIO_Port, &GPIO_InitStruct);

  /*Configure GPIO pin : SPI1_CS_Pin */
  GPIO_InitStruct.Pin = SPI1_CS_Pin;
  GPIO_InitStruct.Mode = GPIO_MODE_OUTPUT_PP;
  GPIO_InitStruct.Pull = GPIO_PULLUP;
  GPIO_InitStruct.Speed = GPIO_SPEED_FREQ_HIGH;
  HAL_GPIO_Init(SPI1_CS_GPIO_Port, &GPIO_InitStruct);

}

void Error_Handler(void)
{
  __disable_irq();
  while (1)
  {
  }
}
